AUTOSAR XML (schema 4-1-3)
standard types defined: boolean, sint32, uint16, uint8
package /UAES/ASW/ApplicationDataTypes
  app type Curr_Ampr_u16: category=VALUE, sw-calibration-access=READ-WRITE, compu {phys=raw*0.1; unit A}, range raw 0..65535, unit=A
  app type q1Em6_s_S32: category=VALUE, sw-calibration-access=READ-WRITE, compu {phys=raw*1e-06}, range phys -2147.483648..2147.483647, raw -2147483648..2147483647
package /UAES/ASW/CompuMethods
  compu method CM_boolean: 0=FALSE, 1=TRUE
package /UAES/ASW/DataTypeMappingSets
  data type mapping set DTMS_KL15PwrSply_Ctrl
    data-type-maps:
      application-data-type=Curr_Ampr_u16, implementation-data-type=uint16
      application-data-type=q1Em6_s_S32, implementation-data-type=sint32
package /UAES/ASW/ImplementationDataTypes
  impl type rt_Array_uint8_29: category=ARRAY
    element rt_Array_uint8_29: array-size=29, array-size-semantics=FIXED-SIZE, implementation-data-type=uint8
package /UAES/ASW/PortInterfaces
  16 x sender receiver interface:
    PwrSply_au8CoornReq: invalidation-policy{data-element=PwrSply_au8CoornReq/Val, handle-invalid=DONT-INVALIDATE}
      data Val: sw-calibration-access=READ-ONLY, type=rt_Array_uint8_29
    PwrSply_au8PwrSup: invalidation-policy{data-element=PwrSply_au8PwrSup/Val, handle-invalid=DONT-INVALIDATE}
      data Val: sw-calibration-access=READ-ONLY, type=rt_Array_uint8_29
    PwrSply_au8PwrSupTime: invalidation-policy{data-element=PwrSply_au8PwrSupTime/Val, handle-invalid=DONT-INVALIDATE}
      data Val: sw-calibration-access=READ-ONLY, type=rt_Array_uint8_29
    PwrSply_au8PwrSupTime_RcvCnt: invalidation-policy{data-element=PwrSply_au8PwrSupTime_RcvCnt/Val, handle-invalid=DONT-INVALIDATE}
      data Val: sw-calibration-access=READ-ONLY, type=rt_Array_uint8_29
    PwrSply_bCCULostComm: invalidation-policy{data-element=PwrSply_bCCULostComm/Val, handle-invalid=DONT-INVALIDATE}
      data Val: sw-calibration-access=READ-ONLY, range raw 0..1, type=boolean
    PwrSply_bNetSleepFlag: invalidation-policy{data-element=PwrSply_bNetSleepFlag/Val, handle-invalid=DONT-INVALIDATE}
      data Val: sw-calibration-access=READ-ONLY, range raw 0..1, type=boolean
    PwrSply_bPositionLightCtrlCmd01: invalidation-policy{data-element=PwrSply_bPositionLightCtrlCmd01/Val, handle-invalid=DONT-INVALIDATE}
      data Val: sw-calibration-access=READ-ONLY, type=boolean
    PwrSply_bPositionLightCtrlCmd02: invalidation-policy{data-element=PwrSply_bPositionLightCtrlCmd02/Val, handle-invalid=DONT-INVALIDATE}
      data Val: sw-calibration-access=READ-ONLY, type=boolean
    PwrSply_bPositionLightCtrlCmd03: invalidation-policy{data-element=PwrSply_bPositionLightCtrlCmd03/Val, handle-invalid=DONT-INVALIDATE}
      data Val: sw-calibration-access=READ-ONLY, type=boolean
    PwrSply_bPositionLightCtrlCmd04: invalidation-policy{data-element=PwrSply_bPositionLightCtrlCmd04/Val, handle-invalid=DONT-INVALIDATE}
      data Val: sw-calibration-access=READ-ONLY, type=boolean
    PwrSply_bPositionLightTimingOFFEnableCfg: invalidation-policy{data-element=PwrSply_bPositionLightTimingOFFEnableCfg/Val, handle-invalid=DONT-INVALIDATE}
      data Val: sw-calibration-access=READ-ONLY, type=boolean
    PwrSply_bVehSpdTkOvr: invalidation-policy{data-element=PwrSply_bVehSpdTkOvr/Val, handle-invalid=DONT-INVALIDATE}
      data Val: sw-calibration-access=READ-ONLY, range raw 0..1, type=boolean
    PwrSply_u8UMM_UsageModeSt: invalidation-policy{data-element=PwrSply_u8UMM_UsageModeSt/Val, handle-invalid=DONT-INVALIDATE}
      data Val: sw-calibration-access=READ-ONLY, range raw 0..255, type=uint8
    PwrSply_u8VehicleTypeCfg: invalidation-policy{data-element=PwrSply_u8VehicleTypeCfg/Val, handle-invalid=DONT-INVALIDATE}
      data Val: sw-calibration-access=READ-ONLY, range raw 0..255, type=uint8
    PwrSply_u8VehRLCM: invalidation-policy{data-element=PwrSply_u8VehRLCM/Val, handle-invalid=DONT-INVALIDATE}
      data Val: sw-calibration-access=READ-ONLY, type=uint8
    PwrSply_u8VMM_OTAModeSt: invalidation-policy{data-element=PwrSply_u8VMM_OTAModeSt/Val, handle-invalid=DONT-INVALIDATE}
      data Val: sw-calibration-access=READ-ONLY, range raw 0..255, type=uint8
package /UAES/ASW/SwComponentTypes
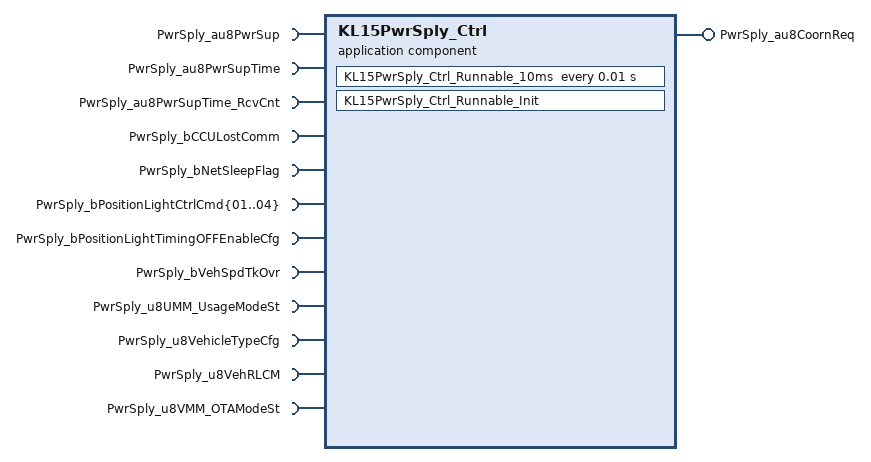
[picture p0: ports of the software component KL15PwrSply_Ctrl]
  application sw component type KL15PwrSply_Ctrl
    provide port PwrSply_au8CoornReq: nonqueued-sender-com-spec{data-element=PwrSply_au8CoornReq/Val, init-value=29 x 0}, provided-interface=PwrSply_au8CoornReq
    15 x require port:
      PwrSply_au8PwrSup: nonqueued-receiver-com-spec{data-element=PwrSply_au8PwrSup/Val, filter=data-filter-type=ALWAYS, init-value=29 x 0}, required-interface=PwrSply_au8PwrSup
      PwrSply_au8PwrSupTime: nonqueued-receiver-com-spec{data-element=PwrSply_au8PwrSupTime/Val, filter=data-filter-type=ALWAYS, init-value=29 x 0}, required-interface=PwrSply_au8PwrSupTime
      PwrSply_au8PwrSupTime_RcvCnt: nonqueued-receiver-com-spec{data-element=PwrSply_au8PwrSupTime_RcvCnt/Val, filter=data-filter-type=ALWAYS, init-value=29 x 0}, required-interface=PwrSply_au8PwrSupTime_RcvCnt
      PwrSply_bCCULostComm: nonqueued-receiver-com-spec{data-element=PwrSply_bCCULostComm/Val, filter=data-filter-type=ALWAYS, init-value=0}, required-interface=PwrSply_bCCULostComm
      PwrSply_bNetSleepFlag: nonqueued-receiver-com-spec{data-element=PwrSply_bNetSleepFlag/Val, filter=data-filter-type=ALWAYS, init-value=0}, required-interface=PwrSply_bNetSleepFlag
      PwrSply_bPositionLightCtrlCmd{01..04}: nonqueued-receiver-com-spec{data-element=PwrSply_bPositionLightCtrlCmd{01..04}/Val, filter=data-filter-type=ALWAYS, init-value=0}, required-interface=PwrSply_bPositionLightCtrlCmd{01..04}
      PwrSply_bPositionLightTimingOFFEnableCfg: nonqueued-receiver-com-spec{data-element=PwrSply_bPositionLightTimingOFFEnableCfg/Val, filter=data-filter-type=ALWAYS, init-value=0}, required-interface=PwrSply_bPositionLightTimingOFFEnableCfg
      PwrSply_bVehSpdTkOvr: nonqueued-receiver-com-spec{data-element=PwrSply_bVehSpdTkOvr/Val, filter=data-filter-type=ALWAYS, init-value=0}, required-interface=PwrSply_bVehSpdTkOvr
      PwrSply_u8UMM_UsageModeSt: nonqueued-receiver-com-spec{data-element=PwrSply_u8UMM_UsageModeSt/Val, filter=data-filter-type=ALWAYS, init-value=0}, required-interface=PwrSply_u8UMM_UsageModeSt
      PwrSply_u8VehicleTypeCfg: nonqueued-receiver-com-spec{data-element=PwrSply_u8VehicleTypeCfg/Val, filter=data-filter-type=ALWAYS, init-value=0}, required-interface=PwrSply_u8VehicleTypeCfg
      PwrSply_u8VehRLCM: nonqueued-receiver-com-spec{data-element=PwrSply_u8VehRLCM/Val, filter=data-filter-type=ALWAYS, init-value=0}, required-interface=PwrSply_u8VehRLCM
      PwrSply_u8VMM_OTAModeSt: nonqueued-receiver-com-spec{data-element=PwrSply_u8VMM_OTAModeSt/Val, filter=data-filter-type=ALWAYS, init-value=0}, required-interface=PwrSply_u8VMM_OTAModeSt
    behavior KL15PwrSply_Ctrl_InternalBehavior: data-type-mapping=DTMS_KL15PwrSply_Ctrl
      timing event TMT_KL15PwrSply_Ctrl_Runnable_10ms: start-on-event=KL15PwrSply_Ctrl_Runnable_10ms, period=0.01
      init event KL15PwrSply_Ctrl_Runnable_InitEvent: start-on-event=KL15PwrSply_Ctrl_Runnable_Init
      runnable KL15PwrSply_Ctrl_Runnable_10ms
        data-read-access:
          15 x access:
            READ_PwrSply_au8PwrSup_Val: accessed-variable=PwrSply_au8PwrSup.Val
            READ_PwrSply_au8PwrSupTime_RcvCnt_Val: accessed-variable=PwrSply_au8PwrSupTime_RcvCnt.Val
            READ_PwrSply_au8PwrSupTime_Val: accessed-variable=PwrSply_au8PwrSupTime.Val
            READ_PwrSply_bCCULostComm_Val: accessed-variable=PwrSply_bCCULostComm.Val
            READ_PwrSply_bEL_FLPositionLightCtrlCmd_Val: accessed-variable=PwrSply_bPositionLightCtrlCmd01.Val
            READ_PwrSply_bEL_FRPositionLightCtrlCmd_Val: accessed-variable=PwrSply_bPositionLightCtrlCmd02.Val
            READ_PwrSply_bNetSleepFlag_Val: accessed-variable=PwrSply_bNetSleepFlag.Val
            READ_PwrSply_bPositionLightCtrlCmd03_Val: accessed-variable=PwrSply_bPositionLightCtrlCmd03.Val
            READ_PwrSply_bPositionLightCtrlCmd04_Val: accessed-variable=PwrSply_bPositionLightCtrlCmd04.Val
            READ_PwrSply_bPositionLightTimingOFFEnableCfg_Val: accessed-variable=PwrSply_bPositionLightTimingOFFEnableCfg.Val
            READ_PwrSply_bVehSpdTkOvr_Val: accessed-variable=PwrSply_bVehSpdTkOvr.Val
            READ_PwrSply_u8UMM_UsageModeSt_Val: accessed-variable=PwrSply_u8UMM_UsageModeSt.Val
            READ_PwrSply_u8VehicleTypeCfg_Val: accessed-variable=PwrSply_u8VehicleTypeCfg.Val
            READ_PwrSply_u8VehRLCM_Val: accessed-variable=PwrSply_u8VehRLCM.Val
            READ_PwrSply_u8VMM_OTAModeSt_Val: accessed-variable=PwrSply_u8VMM_OTAModeSt.Val
        data-write-access:
          access WRITE_PwrSply_au8CoornReq_Val: accessed-variable=PwrSply_au8CoornReq.Val
      runnable KL15PwrSply_Ctrl_Runnable_Init
        data-write-access:
          access WRITE_PwrSply_au8CoornReq_Val: accessed-variable=PwrSply_au8CoornReq.Val
  swc implementation KL15PwrSply_Ctrl_Implementation: behavior=KL15PwrSply_Ctrl_InternalBehavior
    code-descriptors:
      code Default: artifact-descriptors=autosar-engineering-object={short-label=Default, category=SWSRC}
package /UAES/ASW/Units
  unit Curr_A: display-name=A, factor-si-to-unit=1, offset-si-to-unit=0
  unit NoUnit: factor-si-to-unit=1, offset-si-to-unit=0
